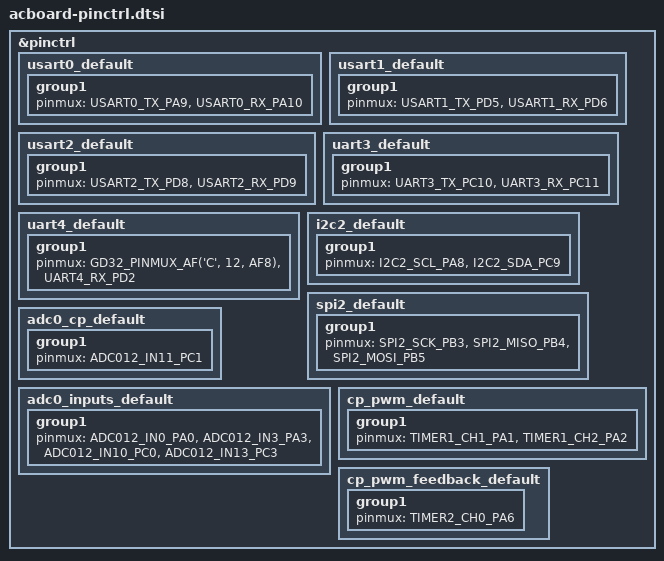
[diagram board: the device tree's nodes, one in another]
/*
 * Copyright (c) 2026
 * SPDX-License-Identifier: Apache-2.0
 */

#include <dt-bindings/pinctrl/gd32f527v(e-g-i-k)xx-pinctrl.h>

&pinctrl {
	usart0_default: usart0_default {
		group1 {
			pinmux = <USART0_TX_PA9>, <USART0_RX_PA10>;
		};
	};

	usart1_default: usart1_default {
		group1 {
			pinmux = <USART1_TX_PD5>, <USART1_RX_PD6>;
		};
	};

	usart2_default: usart2_default {
		group1 {
			pinmux = <USART2_TX_PD8>, <USART2_RX_PD9>;
		};
	};

	uart3_default: uart3_default {
		group1 {
			pinmux = <UART3_TX_PC10>, <UART3_RX_PC11>;
		};
	};

	uart4_default: uart4_default {
		group1 {
			/* The generated pinctrl header mislabels PC12 as UART4_RX. */
			pinmux = <GD32_PINMUX_AF('C', 12, AF8)>, <UART4_RX_PD2>;
		};
	};

	i2c2_default: i2c2_default {
		group1 {
			pinmux = <I2C2_SCL_PA8>, <I2C2_SDA_PC9>;
		};
	};

	spi2_default: spi2_default {
		group1 {
			pinmux = <SPI2_SCK_PB3>,
				 <SPI2_MISO_PB4>,
				 <SPI2_MOSI_PB5>;
		};
	};

	adc0_cp_default: adc0_cp_default {
		group1 {
			pinmux = <ADC012_IN11_PC1>;
		};
	};

	adc0_inputs_default: adc0_inputs_default {
		group1 {
			pinmux = <ADC012_IN0_PA0>,
				 <ADC012_IN3_PA3>,
				 <ADC012_IN10_PC0>,
				 <ADC012_IN13_PC3>;
		};
	};

	cp_pwm_default: cp_pwm_default {
		group1 {
			pinmux = <TIMER1_CH1_PA1>,
				 <TIMER1_CH2_PA2>;
		};
	};

	cp_pwm_feedback_default: cp_pwm_feedback_default {
		group1 {
			pinmux = <TIMER2_CH0_PA6>;
		};
	};
};
